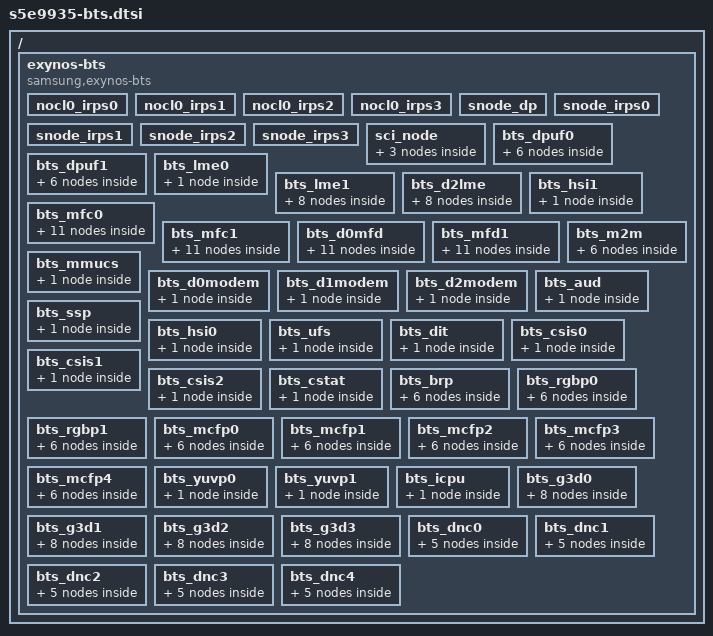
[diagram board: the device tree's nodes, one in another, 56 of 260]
/*
 * SAMSUNG EXYNOS SoC BTS device tree source
 *
 * Copyright (c) 2018 Samsung Electronics Co., Ltd.
 *		http://www.samsung.com
 *
 * SAMSUNG EXYNOS SoC BTS device nodes are listed in this file.
 * EXYNOS based board files should include this file.
 *
 * This program is free software; you can redistribute it and/or modify
 * it under the terms of the GNU General Public License version 2 as
 * published by the Free Software Foundation.
 *
 */

#include <dt-bindings/soc/samsung/exynos-bts.h>

/*
 * TREX_D_DNC		0x166F0000
 * TREX_D_NOCL0		0x1A4E0000
 * TREX_D_NOCL1A	0x1A7E0000
 * TREX_D_NOCL1B	0x1A930000
 * TREX_D_NOCL1C	0x1A6E0000
 */

/ {
	exynos-bts {
		compatible = "samsung,exynos-bts";
		acpm-ipc-channel = <8>;
		vch_pd_calid = <0xB1380017>, <0xB1380002>;
		#address-cells = <2>;
		#size-cells = <1>;
		ranges;

		list-scen = "default",
			"cp_throughput",
			"mfc_uhd",
			"mfc_uhd_10bit",
			"mfc_8k_dec30",
			"gdc_8k_8b_30",
			"gdc_8k_8b_60",
			"g3d_heavy",
			"g3d_performance",
			"dp_default",
			"camera_default",
			"npu_normal",
			"mfc_uhd_enc60",
			"camera_heavy",
			"npu_performance";

	        /* num_channel, mif_bus_width, bus_width, mif_util, int_util*/
	        bw_params = <4 16 32 65 70>;

		/* IRPS0/1/2/3 SCI_CTL_SCI_CTRL*/
		nocl0_irps0 {
			#address-cells = <2>;
			#size-cells = <1>;
			ranges;
			reg = <0x0 0x1A4EA000 0x40>;
			status = "okay";
			bts-type = <TREX_BTS>;
		};
		nocl0_irps1 {
			reg = <0x0 0x1A4EA040 0x40>;
			status = "okay";
			bts-type = <TREX_BTS>;
		};
		nocl0_irps2 {
			reg = <0x0 0x1A4EA080 0x40>;
			status = "okay";
			bts-type = <TREX_BTS>;
		};
		nocl0_irps3 {
			reg = <0x0 0x1A4EA0C0 0x40>;
			status = "okay";
			bts-type = <TREX_BTS>;
		};
		/* QMAX THRESHOLD */
		snode_dp {
			reg = <0x0 0x1A4EB040 0x8>;
			status = "okay";
			bts-type = <BUSC_BTS>;
		};
		snode_irps0 {
			reg = <0x0 0x1A4EB000 0x8>;
			status = "okay";
			bts-type = <BUSC_BTS>;
		};
		snode_irps1 {
			reg = <0x0 0x1A4EB010 0x8>;
			status = "okay";
			bts-type = <BUSC_BTS>;
		};
		snode_irps2 {
			reg = <0x0 0x1A4EB020 0x8>;
			status = "okay";
			bts-type = <BUSC_BTS>;
		};
		snode_irps3 {
			reg = <0x0 0x1A4EB030 0x8>;
			status = "okay";
			bts-type = <BUSC_BTS>;
		};
		sci_node {
			reg = <0x0 0x1A000100 0x100>;
			status = "okay";
			bts-type = <SCI_BTS>;
			default {
				stat_on = <1>;
				rmo = <0x0>;
				wmo = <0x0>;
			};
			camera_default {
				stat_on = <1>;
				rmo = <0x8>;
				wmo = <0x8>;
			};
			camera_heavy {
				stat_on = <1>;
				rmo = <0x8>;
				wmo = <0x8>;
			};
		};
		/* NOCL1A D0_DPUF0 */
		bts_dpuf0 {
			reg = <0x0 0x1A7E8000 0x80>;
			status = "okay";
			bts-type = <IP_BTS>;
			default {
				stat_on = <1>;
				bypass = <0>;
				arqos = <0x8>;
				awqos = <0x8>;
				qurgent_on = <0xC>;
				qurgent_th_r = <0x14>;
				blocking_on = <0>;
			};
			camera_default {
				stat_on = <1>;
				bypass = <0>;
				arqos = <0x8>;
				awqos = <0x8>;
				rmo = <0x20>;
				wmo = <0x20>;
				qurgent_on = <0>;
				blocking_on = <0>;
			};
			npu_normal {
				stat_on = <1>;
				bypass = <0>;
				arqos = <0x8>;
				awqos = <0x8>;
				rmo = <0x20>;
				wmo = <0x20>;
				qurgent_on = <0>;
				blocking_on = <0>;
			};
			mfc_uhd_enc60 {
				stat_on = <1>;
				bypass = <0>;
				arqos = <0x8>;
				awqos = <0x8>;
				rmo = <0x20>;
				wmo = <0x20>;
				qurgent_on = <0>;
				blocking_on = <0>;
			};
			camera_heavy {
				stat_on = <1>;
				bypass = <0>;
				arqos = <0x8>;
				awqos = <0x8>;
				rmo = <0x20>;
				wmo = <0x20>;
				qurgent_on = <0>;
				blocking_on = <0>;
			};
			npu_performance {
				stat_on = <1>;
				bypass = <0>;
				arqos = <0x8>;
				awqos = <0x8>;
				rmo = <0x20>;
				wmo = <0x20>;
				qurgent_on = <0>;
				blocking_on = <0>;
			};
		};
		/* NOCL1A D1_DPUF0 */
		bts_dpuf1 {
			reg = <0x0 0x1A7E8080 0x80>;
			status = "okay";
			bts-type = <IP_BTS>;
			default {
				stat_on = <1>;
				bypass = <0>;
				arqos = <0x8>;
				awqos = <0x8>;
				qurgent_on = <0xC>;
				qurgent_th_r = <0x14>;
				blocking_on = <0>;
			};
			camera_default {
				stat_on = <1>;
				bypass = <0>;
				arqos = <0x8>;
				awqos = <0x8>;
				rmo = <0x20>;
				wmo = <0x20>;
				qurgent_on = <0>;
				blocking_on = <0>;
			};
			npu_normal {
				stat_on = <1>;
				bypass = <0>;
				arqos = <0x8>;
				awqos = <0x8>;
				rmo = <0x20>;
				wmo = <0x20>;
				qurgent_on = <0>;
				blocking_on = <0>;
			};
			mfc_uhd_enc60 {
				stat_on = <1>;
				bypass = <0>;
				arqos = <0x8>;
				awqos = <0x8>;
				rmo = <0x20>;
				wmo = <0x20>;
				qurgent_on = <0>;
				blocking_on = <0>;
			};
			camera_heavy {
				stat_on = <1>;
				bypass = <0>;
				arqos = <0x8>;
				awqos = <0x8>;
				rmo = <0x20>;
				wmo = <0x20>;
				qurgent_on = <0>;
				blocking_on = <0>;
			};
			npu_performance {
				stat_on = <1>;
				bypass = <0>;
				arqos = <0x8>;
				awqos = <0x8>;
				rmo = <0x20>;
				wmo = <0x20>;
				qurgent_on = <0>;
				blocking_on = <0>;
			};
		};
		/* NOCL1A D0LME */
		bts_lme0 {
			reg = <0x0 0x1A7E8100 0x80>;
			status = "okay";
			bts-type = <IP_BTS>;
			default {
				stat_on = <1>;
				bypass = <0>;
				arqos = <0x4>;
				awqos = <0x4>;
				rmo = <0x4>;
				wmo = <0x8>;
				qurgent_on = <0>;
				blocking_on = <0>;
			};
		};
		/* NOCL1A D1LME */
		bts_lme1 {
			reg = <0x0 0x1A7E8180 0x80>;
			status = "okay";
			bts-type = <IP_BTS>;
			default {
				stat_on = <1>;
				bypass = <0>;
				arqos = <0x4>;
				awqos = <0x4>;
				rmo = <0x4>;
				wmo = <0x8>;
				qurgent_on = <0>;
				blocking_on = <0>;
			};
			gdc_8k_8b_30 {
				stat_on = <1>;
				bypass = <0>;
				arqos = <0x4>;
				awqos = <0x4>;
				rmo = <0x3C>;
				wmo = <0x14>;
				qurgent_on = <0>;
				blocking_on = <0>;
			};
			gdc_8k_8b_60 {
				stat_on = <1>;
				bypass = <0>;
				arqos = <0x4>;
				awqos = <0x4>;
				rmo = <0x84>;
				wmo = <0x28>;
				qurgent_on = <0>;
				blocking_on = <0>;
			};
			camera_default {
				stat_on = <1>;
				bypass = <0>;
				arqos = <0x4>;
				awqos = <0x4>;
				rmo = <0x28>;
				wmo = <0x8>;
				qurgent_on = <0>;
				blocking_on = <0>;
			};
			npu_normal {
				stat_on = <1>;
				bypass = <0>;
				arqos = <0x4>;
				awqos = <0x4>;
				rmo = <0x28>;
				wmo = <0x8>;
				qurgent_on = <0>;
				blocking_on = <0>;
			};
			mfc_uhd_enc60 {
				stat_on = <1>;
				bypass = <0>;
				arqos = <0x4>;
				awqos = <0x4>;
				rmo = <0x4>;
				wmo = <0x8>;
				qurgent_on = <0>;
				blocking_on = <0>;
			};
			camera_heavy {
				stat_on = <1>;
				bypass = <0>;
				arqos = <0x4>;
				awqos = <0x4>;
				rmo = <0x28>;
				wmo = <0x8>;
				qurgent_on = <0>;
				blocking_on = <0>;
			};
			npu_performance {
				stat_on = <1>;
				bypass = <0>;
				arqos = <0x4>;
				awqos = <0x4>;
				rmo = <0x4>;
				wmo = <0x8>;
				qurgent_on = <0>;
				blocking_on = <0>;
			};
		};
		/* NOCL1A D2LME */
		bts_d2lme {
			reg = <0x0 0x1A7E8200 0x80>;
			status = "okay";
			bts-type = <IP_BTS>;
			default {
				stat_on = <1>;
				bypass = <0>;
				arqos = <0x4>;
				awqos = <0x4>;
				rmo = <0xC>;
				wmo = <0xC>;
				qurgent_on = <0>;
				blocking_on = <0>;
			};
			gdc_8k_8b_30 {
				stat_on = <1>;
				bypass = <0>;
				arqos = <0x4>;
				awqos = <0x4>;
				rmo = <0xC>;
				wmo = <0xC>;
				qurgent_on = <0>;
				blocking_on = <0>;
			};
			gdc_8k_8b_60 {
				stat_on = <1>;
				bypass = <0>;
				arqos = <0x4>;
				awqos = <0x4>;
				rmo = <0xC>;
				wmo = <0xC>;
				qurgent_on = <0>;
				blocking_on = <0>;
			};
			camera_default {
				stat_on = <1>;
				bypass = <0>;
				arqos = <0x4>;
				awqos = <0x4>;
				rmo = <0xC>;
				wmo = <0xC>;
				qurgent_on = <0>;
				blocking_on = <0>;
			};
			npu_normal {
				stat_on = <1>;
				bypass = <0>;
				arqos = <0x4>;
				awqos = <0x4>;
				rmo = <0xC>;
				wmo = <0xC>;
				qurgent_on = <0>;
				blocking_on = <0>;
			};
			mfc_uhd_enc60 {
				stat_on = <1>;
				bypass = <0>;
				arqos = <0x4>;
				awqos = <0x4>;
				rmo = <0xC>;
				wmo = <0xC>;
				qurgent_on = <0>;
				blocking_on = <0>;
			};
			camera_heavy {
				stat_on = <1>;
				bypass = <0>;
				arqos = <0x4>;
				awqos = <0x4>;
				rmo = <0xE>;
				wmo = <0xE>;
				qurgent_on = <0>;
				blocking_on = <0>;
			};
			npu_performance {
				stat_on = <1>;
				bypass = <0>;
				arqos = <0x4>;
				awqos = <0x4>;
				rmo = <0xC>;
				wmo = <0xC>;
				qurgent_on = <0>;
				blocking_on = <0>;
			};
		};
		/* NOCL1A HSI1 */
		bts_hsi1 {
			reg = <0x0 0x1A7E8280 0x80>;
			status = "okay";
			bts-type = <IP_BTS>;
			default {
				stat_on = <1>;
				bypass = <0>;
				arqos = <0x4>;
				awqos = <0x4>;
				rmo = <0x4>;
				wmo = <0x4>;
				qurgent_on = <0>;
				blocking_on = <1>;
				qmax0_limit_r = <0x1>;
				qmax0_limit_w = <0x1>;
			};
		};
		/* NOCL1A D0_MFC */
		bts_mfc0 {
			reg = <0x0 0x1A7E8300 0x80>;
			status = "okay";
			bts-type = <IP_BTS>;
			default {
				stat_on = <1>;
				bypass = <0>;
				arqos = <0x4>;
				awqos = <0x4>;
				rmo = <0x1C>;
				wmo = <0xC>;
				qurgent_on = <0>;
				blocking_on = <0>;
			};
			mfc_uhd {
				stat_on = <1>;
				bypass = <0>;
				arqos = <0x4>;
				awqos = <0x4>;
				rmo = <0x20>;
				wmo = <0x20>;
				qurgent_on = <0>;
				blocking_on = <0>;
			};
			mfc_uhd_10bit {
				stat_on = <1>;
				bypass = <0>;
				arqos = <0x4>;
				awqos = <0x4>;
				rmo = <0x20>;
				wmo = <0x20>;
				qurgent_on = <0>;
				blocking_on = <0>;
			};
			mfc_8k_dec30 {
				stat_on = <1>;
				bypass = <0>;
				arqos = <0x4>;
				awqos = <0x4>;
				rmo = <0x40>;
				wmo = <0x40>;
				qurgent_on = <0>;
				blocking_on = <0>;
			};
			g3d_performance {
				stat_on = <1>;
				bypass = <0>;
				arqos = <0x4>;
				awqos = <0x4>;
				rmo = <0x20>;
				wmo = <0x20>;
				qurgent_on = <0>;
				blocking_on = <0>;
			};
			dp_default {
				stat_on = <1>;
				bypass = <0>;
				arqos = <0x4>;
				awqos = <0x4>;
				rmo = <0x20>;
				wmo = <0x20>;
				qurgent_on = <0>;
				blocking_on = <0>;
			};
			camera_default {
				stat_on = <1>;
				bypass = <0>;
				arqos = <0x4>;
				awqos = <0x4>;
				rmo = <0x1C>;
				wmo = <0xC>;
				qurgent_on = <0>;
				blocking_on = <0>;
			};
			npu_normal {
				stat_on = <1>;
				bypass = <0>;
				arqos = <0x4>;
				awqos = <0x4>;
				rmo = <0x1C>;
				wmo = <0xC>;
				qurgent_on = <0>;
				blocking_on = <0>;
			};
			mfc_uhd_enc60 {
				stat_on = <1>;
				bypass = <0>;
				arqos = <0x4>;
				awqos = <0x4>;
				rmo = <0x20>;
				wmo = <0x20>;
				qurgent_on = <0>;
				blocking_on = <0>;
			};
			camera_heavy {
				stat_on = <1>;
				bypass = <0>;
				arqos = <0x4>;
				awqos = <0x4>;
				rmo = <0x1C>;
				wmo = <0xC>;
				qurgent_on = <0>;
				blocking_on = <0>;
			};
			npu_performance {
				stat_on = <1>;
				bypass = <0>;
				arqos = <0x4>;
				awqos = <0x4>;
				rmo = <0x1C>;
				wmo = <0xC>;
				qurgent_on = <0>;
				blocking_on = <0>;
			};
		};
		/* NOCL1A D1_MFC */
		bts_mfc1 {
			reg = <0x0 0x1A7E8380 0x80>;
			status = "okay";
			bts-type = <IP_BTS>;
			default {
				stat_on = <1>;
				bypass = <0>;
				arqos = <0x4>;
				awqos = <0x4>;
				rmo = <0x1C>;
				wmo = <0xC>;
				qurgent_on = <0>;
				blocking_on = <0>;
			};
			mfc_uhd {
				stat_on = <1>;
				bypass = <0>;
				arqos = <0x4>;
				awqos = <0x4>;
				rmo = <0x20>;
				wmo = <0x20>;
				qurgent_on = <0>;
				blocking_on = <0>;
			};
			mfc_uhd_10bit {
				stat_on = <1>;
				bypass = <0>;
				arqos = <0x4>;
				awqos = <0x4>;
				rmo = <0x20>;
				wmo = <0x20>;
				qurgent_on = <0>;
				blocking_on = <0>;
			};
			mfc_8k_dec30 {
				stat_on = <1>;
				bypass = <0>;
				arqos = <0x4>;
				awqos = <0x4>;
				rmo = <0x40>;
				wmo = <0x40>;
				qurgent_on = <0>;
				blocking_on = <0>;
			};
			g3d_performance {
				stat_on = <1>;
				bypass = <0>;
				arqos = <0x4>;
				awqos = <0x4>;
				rmo = <0x20>;
				wmo = <0x20>;
				qurgent_on = <0>;
				blocking_on = <0>;
			};
			dp_default {
				stat_on = <1>;
				bypass = <0>;
				arqos = <0x4>;
				awqos = <0x4>;
				rmo = <0x20>;
				wmo = <0x20>;
				qurgent_on = <0>;
				blocking_on = <0>;
			};
			camera_default {
				stat_on = <1>;
				bypass = <0>;
				arqos = <0x4>;
				awqos = <0x4>;
				rmo = <0x1C>;
				wmo = <0xC>;
				qurgent_on = <0>;
				blocking_on = <0>;
			};
			npu_normal {
				stat_on = <1>;
				bypass = <0>;
				arqos = <0x4>;
				awqos = <0x4>;
				rmo = <0x1C>;
				wmo = <0xC>;
				qurgent_on = <0>;
				blocking_on = <0>;
			};
			mfc_uhd_enc60 {
				stat_on = <1>;
				bypass = <0>;
				arqos = <0x4>;
				awqos = <0x4>;
				rmo = <0x20>;
				wmo = <0x20>;
				qurgent_on = <0>;
				blocking_on = <0>;
			};
			camera_heavy {
				stat_on = <1>;
				bypass = <0>;
				arqos = <0x4>;
				awqos = <0x4>;
				rmo = <0x1C>;
				wmo = <0xC>;
				qurgent_on = <0>;
				blocking_on = <0>;
			};
			npu_performance {
				stat_on = <1>;
				bypass = <0>;
				arqos = <0x4>;
				awqos = <0x4>;
				rmo = <0x1C>;
				wmo = <0xC>;
				qurgent_on = <0>;
				blocking_on = <0>;
			};
		};
		/* NOCL1A D0_MFD */
		bts_d0mfd {
			reg = <0x0 0x1A7E8400 0x80>;
			status = "okay";
			bts-type = <IP_BTS>;
			default {
				stat_on = <1>;
				bypass = <0>;
				arqos = <0x4>;
				awqos = <0x4>;
				rmo = <0x1C>;
				wmo = <0xC>;
				qurgent_on = <0>;
				blocking_on = <0>;
			};
			mfc_uhd {
				stat_on = <1>;
				bypass = <0>;
				arqos = <0x4>;
				awqos = <0x4>;
				rmo = <0x20>;
				wmo = <0x20>;
				qurgent_on = <0>;
				blocking_on = <0>;
			};
			mfc_uhd_10bit {
				stat_on = <1>;
				bypass = <0>;
				arqos = <0x4>;
				awqos = <0x4>;
				rmo = <0x20>;
				wmo = <0x20>;
				qurgent_on = <0>;
				blocking_on = <0>;
			};
			mfc_8k_dec30 {
				stat_on = <1>;
				bypass = <0>;
				arqos = <0x4>;
				awqos = <0x4>;
				rmo = <0x40>;
				wmo = <0x40>;
				qurgent_on = <0>;
				blocking_on = <0>;
			};
			g3d_performance {
				stat_on = <1>;
				bypass = <0>;
				arqos = <0x4>;
				awqos = <0x4>;
				rmo = <0x20>;
				wmo = <0x20>;
				qurgent_on = <0>;
				blocking_on = <0>;
			};
			dp_default {
				stat_on = <1>;
				bypass = <0>;
				arqos = <0x4>;
				awqos = <0x4>;
				rmo = <0x20>;
				wmo = <0x20>;
				qurgent_on = <0>;
				blocking_on = <0>;
			};
			camera_default {
				stat_on = <1>;
				bypass = <0>;
				arqos = <0x4>;
				awqos = <0x4>;
				rmo = <0x1C>;
				wmo = <0xC>;
				qurgent_on = <0>;
				blocking_on = <0>;
			};
			npu_normal {
				stat_on = <1>;
				bypass = <0>;
				arqos = <0x4>;
				awqos = <0x4>;
				rmo = <0x1C>;
				wmo = <0xC>;
				qurgent_on = <0>;
				blocking_on = <0>;
			};
			mfc_uhd_enc60 {
				stat_on = <1>;
				bypass = <0>;
				arqos = <0x4>;
				awqos = <0x4>;
				rmo = <0x20>;
				wmo = <0x20>;
				qurgent_on = <0>;
				blocking_on = <0>;
			};
			camera_heavy {
				stat_on = <1>;
				bypass = <0>;
				arqos = <0x4>;
				awqos = <0x4>;
				rmo = <0x1C>;
				wmo = <0xC>;
				qurgent_on = <0>;
				blocking_on = <0>;
			};
			npu_performance {
				stat_on = <1>;
				bypass = <0>;
				arqos = <0x4>;
				awqos = <0x4>;
				rmo = <0x20>;
				wmo = <0x20>;
				qurgent_on = <0>;
				blocking_on = <0>;
			};
		};
		/* NOCL1A D1_MFD */
		bts_mfd1 {
			reg = <0x0 0x1A7E8480 0x80>;
			status = "okay";
			bts-type = <IP_BTS>;
			default {
				stat_on = <1>;
				bypass = <0>;
				arqos = <0x4>;
				awqos = <0x4>;
				rmo = <0x1C>;
				wmo = <0xC>;
				qurgent_on = <0>;
				blocking_on = <0>;
			};
			mfc_uhd {
				stat_on = <1>;
				bypass = <0>;
				arqos = <0x4>;
				awqos = <0x4>;
				rmo = <0x20>;
				wmo = <0x20>;
				qurgent_on = <0>;
				blocking_on = <0>;
			};
			mfc_uhd_10bit {
				stat_on = <1>;
				bypass = <0>;
				arqos = <0x4>;
				awqos = <0x4>;
				rmo = <0x20>;
				wmo = <0x20>;
				qurgent_on = <0>;
				blocking_on = <0>;
			};
			mfc_8k_dec30 {
				stat_on = <1>;
				bypass = <0>;
				arqos = <0x4>;
				awqos = <0x4>;
				rmo = <0x40>;
				wmo = <0x40>;
				qurgent_on = <0>;
				blocking_on = <0>;
			};
			g3d_performance {
				stat_on = <1>;
				bypass = <0>;
				arqos = <0x4>;
				awqos = <0x4>;
				rmo = <0x20>;
				wmo = <0x20>;
				qurgent_on = <0>;
				blocking_on = <0>;
			};
			dp_default {
				stat_on = <1>;
				bypass = <0>;
				arqos = <0x4>;
				awqos = <0x4>;
				rmo = <0x20>;
				wmo = <0x20>;
				qurgent_on = <0>;
				blocking_on = <0>;
			};
			camera_default {
				stat_on = <1>;
				bypass = <0>;
				arqos = <0x4>;
				awqos = <0x4>;
				rmo = <0x1C>;
				wmo = <0xC>;
				qurgent_on = <0>;
				blocking_on = <0>;
			};
			npu_normal {
				stat_on = <1>;
				bypass = <0>;
				arqos = <0x4>;
				awqos = <0x4>;
				rmo = <0x1C>;
				wmo = <0xC>;
				qurgent_on = <0>;
				blocking_on = <0>;
			};
			mfc_uhd_enc60 {
				stat_on = <1>;
				bypass = <0>;
				arqos = <0x4>;
				awqos = <0x4>;
				rmo = <0x20>;
				wmo = <0x20>;
				qurgent_on = <0>;
				blocking_on = <0>;
			};
			camera_heavy {
				stat_on = <1>;
				bypass = <0>;
				arqos = <0x4>;
				awqos = <0x4>;
				rmo = <0x1C>;
				wmo = <0xC>;
				qurgent_on = <0>;
				blocking_on = <0>;
			};
			npu_performance {
				stat_on = <1>;
				bypass = <0>;
				arqos = <0x4>;
				awqos = <0x4>;
				rmo = <0x1C>;
				wmo = <0xC>;
				qurgent_on = <0>;
				blocking_on = <0>;
			};
		};
		/* NOCL1A M2M */
		bts_m2m {
			reg = <0x0 0x1A7E8500 0x100>;
			status = "okay";
			bts-type = <IP_BTS>;
			default {
				stat_on = <1>;
				bypass = <0>;
				arqos = <0x4>;
				awqos = <0x4>;
				rmo = <0x18>;
				wmo = <0x18>;
				qurgent_on = <0>;
				blocking_on = <1>;
				qmax0_limit_r = <0x8>;
				qmax0_limit_w = <0x8>;
			};
			camera_default {
				stat_on = <1>;
				bypass = <0>;
				arqos = <0x4>;
				awqos = <0x4>;
				rmo = <0x8>;
				wmo = <0x8>;
				qurgent_on = <0>;
				blocking_on = <0>;
			};
			npu_normal {
				stat_on = <1>;
				bypass = <0>;
				arqos = <0x4>;
				awqos = <0x4>;
				rmo = <0x8>;
				wmo = <0x8>;
				qurgent_on = <0>;
				blocking_on = <0>;
			};
			mfc_uhd_enc60 {
				stat_on = <1>;
				bypass = <0>;
				arqos = <0x4>;
				awqos = <0x4>;
				rmo = <0x8>;
				wmo = <0x8>;
				qurgent_on = <0>;
				blocking_on = <0>;
			};
			camera_heavy {
				stat_on = <1>;
				bypass = <0>;
				arqos = <0x4>;
				awqos = <0x4>;
				rmo = <0x20>;
				wmo = <0x20>;
				qurgent_on = <0>;
				blocking_on = <0>;
			};
			npu_performance {
				stat_on = <1>;
				bypass = <0>;
				arqos = <0x4>;
				awqos = <0x4>;
				rmo = <0x8>;
				wmo = <0x8>;
				qurgent_on = <0>;
				blocking_on = <0>;
			};
		};
		/* NOCL0 MMUCS */
		bts_mmucs {
			reg = <0x0 0x1A4E8000 0x80>;
			status = "okay";
			bts-type = <IP_BTS>;
			default {
				stat_on = <1>;
				bypass = <0>;
				arqos = <0x4>;
				awqos = <0x4>;
				rmo = <0x4>;
				wmo = <0x4>;
				qurgent_on = <0x0>;
				blocking_on = <0>;
			};
		};
		/* NOCL0 D0_MODEM */
		bts_d0modem {
			reg = <0x0 0x1A4E8080 0x80>;
			status = "okay";
			bts-type = <IP_BTS>;
			default {
				stat_on = <1>;
				bypass = <0>;
				arqos = <0xC>;
				awqos = <0xC>;
				rmo = <0x20>;
				wmo = <0x20>;
				qurgent_on = <0xC>;
				qurgent_th_r = <0x14>;
				qurgent_th_w = <0x14>;
				blocking_on = <0>;
			};
		};
		/* NOCL0 D1_MODEM */
		bts_d1modem {
			reg = <0x0 0x1A4E8100 0x80>;
			status = "okay";
			bts-type = <IP_BTS>;
			default {
				stat_on = <1>;
				bypass = <1>;
				rmo = <0x14>;
				wmo = <0x14>;
				qurgent_on = <0>;
				blocking_on = <0>;
			};
		};
		/* NOCL0 D2_MODEM */
		bts_d2modem {
			reg = <0x0 0x1A4E8180 0x80>;
			status = "okay";
			bts-type = <IP_BTS>;
			default {
				stat_on = <1>;
				bypass = <0>;
				arqos = <0x4>;
				awqos = <0x4>;
				rmo = <0x14>;
				wmo = <0x8>;
				qurgent_on = <0x0>;
				blocking_on = <0>;
			};
		};
		/* NOCL0 AUD */
		bts_aud {
			reg = <0x0 0x1A4E8200 0x80>;
			status = "okay";
			bts-type = <IP_BTS>;
			default {
				stat_on = <1>;
				bypass = <0>;
				arqos = <0x9>;
				awqos = <0x9>;
				qurgent_on = <0xC>;
				qurgent_th_r = <0x14>;
				qurgent_th_w = <0x14>;
				blocking_on = <0>;
			};
		};
		/* NOCL0 SSP */
		bts_ssp {
			reg = <0x0 0x1A4E8280 0x80>;
			status = "okay";
			bts-type = <IP_BTS>;
			default {
				stat_on = <1>;
				bypass = <0>;
				arqos = <0x4>;
				awqos = <0x4>;
				rmo = <0x4>;
				wmo = <0x4>;
				qurgent_on = <0>;
				blocking_on = <0>;
			};
		};
		/* NOCL1B HSI0 */
		bts_hsi0 {
			reg = <0x0 0x1A938000 0x80>;
			status = "okay";
			bts-type = <IP_BTS>;
			default {
				stat_on = <1>;
				bypass = <0>;
				arqos = <0x4>;
				awqos = <0x4>;
				rmo = <0x4>;
				wmo = <0x4>;
				qurgent_on = <0>;
				blocking_on = <1>;
				qmax0_limit_r = <0x1>;
				qmax0_limit_w = <0x1>;
			};
		};
		/* NOCL1B ufs */
		bts_ufs {
			reg = <0x0 0x1A938080 0x80>;
			status = "okay";
			bts-type = <IP_BTS>;
			default {
				stat_on = <1>;
				bypass = <0>;
				arqos = <0x4>;
				awqos = <0x4>;
				rmo = <0xC>;
				wmo = <0xC>;
				qurgent_on = <0>;
				blocking_on = <1>;
				qmax0_limit_r = <0x1>;
				qmax0_limit_w = <0x1>;
			};
		};
		/* NOCL1B DIT */
		bts_dit {
			reg = <0x0 0x1A938100 0x80>;
			status = "okay";
			bts-type = <IP_BTS>;
			default {
				stat_on = <1>;
				bypass = <0>;
				arqos = <0x4>;
				awqos = <0x4>;
				rmo = <0x4>;
				wmo = <0x4>;
				qurgent_on = <0>;
				blocking_on = <1>;
				qmax0_limit_r = <0x1>;
				qmax0_limit_w = <0x1>;
			};
		};
		/* NOCL1C D0_CSIS */
		bts_csis0 {
			reg = <0x0 0x1A6E8000 0x80>;
			status = "okay";
			bts-type = <IP_BTS>;
			cal-pdid = <0xB1380002>;
			default {
				stat_on = <1>;
				bypass = <0>;
				arqos = <0xC>;
				awqos = <0xC>;
				qurgent_on = <0xC>;
				qurgent_th_r = <0x14>;
				qurgent_th_w = <0xD>;
				blocking_on = <0>;
			};
		};
		/* NOCL1C D1_CSIS */
		bts_csis1 {
			reg = <0x0 0x1A6E8080 0x80>;
			status = "okay";
			bts-type = <IP_BTS>;
			cal-pdid = <0xB1380002>;
			default {
				stat_on = <1>;
				bypass = <0>;
				arqos = <0xC>;
				awqos = <0xC>;
				qurgent_on = <0xC>;
				qurgent_th_r = <0x14>;
				qurgent_th_w = <0xD>;
				blocking_on = <0>;
			};
		};
		/* NOCL1C D2_CSIS */
		bts_csis2 {
			reg = <0x0 0x1A6E8100 0x80>;
			status = "okay";
			bts-type = <IP_BTS>;
			cal-pdid = <0xB1380002>;
			default {
				stat_on = <1>;
				bypass = <0>;
				arqos = <0xC>;
				awqos = <0xC>;
				qurgent_on = <0xC>;
				qurgent_th_r = <0x14>;
				qurgent_th_w = <0xD>;
				blocking_on = <0>;
			};
		};
		/* NOCL1C CSTAT */
		bts_cstat {
			reg = <0x0 0x1A6E8180 0x80>;
			status = "okay";
			bts-type = <IP_BTS>;
			cal-pdid = <0xB1380002>;
			default {
				stat_on = <1>;
				bypass = <0>;
				arqos = <0xC>;
				awqos = <0xC>;
				qurgent_on = <0xC>;
				qurgent_th_r = <0x14>;
				qurgent_th_w = <0xD>;
				blocking_on = <0>;
			};
		};
		/* NOCL1C BRP */
		bts_brp {
			reg = <0x0 0x1A6E8200 0x80>;
			status = "okay";
			bts-type = <IP_BTS>;
			cal-pdid = <0xB1380002>;
			default {
				stat_on = <1>;
				bypass = <0>;
				arqos = <0x4>;
				awqos = <0x4>;
				rmo = <0x4>;
				wmo = <0x8>;
				qurgent_on = <0>;
				blocking_on = <0>;
			};
			camera_default {
				stat_on = <1>;
				bypass = <0>;
				arqos = <0x4>;
				awqos = <0x4>;
				rmo = <0x10>;
				wmo = <0x8>;
				qurgent_on = <0>;
				blocking_on = <0>;
			};
			npu_normal {
				stat_on = <1>;
				bypass = <0>;
				arqos = <0x4>;
				awqos = <0x4>;
				rmo = <0x10>;
				wmo = <0x8>;
				qurgent_on = <0>;
				blocking_on = <0>;
			};
			mfc_uhd_enc60 {
				stat_on = <1>;
				bypass = <0>;
				arqos = <0x4>;
				awqos = <0x4>;
				rmo = <0x4>;
				wmo = <0x8>;
				qurgent_on = <0>;
				blocking_on = <0>;
			};
			camera_heavy {
				stat_on = <1>;
				bypass = <0>;
				arqos = <0x4>;
				awqos = <0x4>;
				rmo = <0x20>;
				wmo = <0x20>;
				qurgent_on = <0>;
				blocking_on = <0>;
			};
			npu_performance {
				stat_on = <1>;
				bypass = <0>;
				arqos = <0x4>;
				awqos = <0x4>;
				rmo = <0x4>;
				wmo = <0x8>;
				qurgent_on = <0>;
				blocking_on = <0>;
			};

		};
		/* NOCL1C D0_RGBP */
		bts_rgbp0 {
			reg = <0x0 0x1A6E8280 0x80>;
			status = "okay";
			bts-type = <IP_BTS>;
			cal-pdid = <0xB1380002>;
			default {
				stat_on = <1>;
				bypass = <0>;
				arqos = <0x4>;
				awqos = <0x4>;
				rmo = <0x4>;
				wmo = <0x8>;
				qurgent_on = <0>;
				blocking_on = <0>;
			};
			camera_default {
				stat_on = <1>;
				bypass = <0>;
				arqos = <0x4>;
				awqos = <0x4>;
				rmo = <0x10>;
				wmo = <0x8>;
				qurgent_on = <0>;
				blocking_on = <0>;
			};
			npu_normal {
				stat_on = <1>;
				bypass = <0>;
				arqos = <0x4>;
				awqos = <0x4>;
				rmo = <0x10>;
				wmo = <0x8>;
				qurgent_on = <0>;
				blocking_on = <0>;
			};
			mfc_uhd_enc60 {
				stat_on = <1>;
				bypass = <0>;
				arqos = <0x4>;
				awqos = <0x4>;
				rmo = <0x4>;
				wmo = <0x8>;
				qurgent_on = <0>;
				blocking_on = <0>;
			};
			camera_heavy {
				stat_on = <1>;
				bypass = <0>;
				arqos = <0x4>;
				awqos = <0x4>;
				rmo = <0x20>;
				wmo = <0x20>;
				qurgent_on = <0>;
				blocking_on = <0>;
			};
			npu_performance {
				stat_on = <1>;
				bypass = <0>;
				arqos = <0x4>;
				awqos = <0x4>;
				rmo = <0x4>;
				wmo = <0x8>;
				qurgent_on = <0>;
				blocking_on = <0>;
			};

		};
		/* NOCL1C D1_RGBP */
		bts_rgbp1 {
			reg = <0x0 0x1A6E8300 0x80>;
			status = "okay";
			bts-type = <IP_BTS>;
			cal-pdid = <0xB1380002>;
			default {
				stat_on = <1>;
				bypass = <0>;
				arqos = <0x4>;
				awqos = <0x4>;
				rmo = <0x4>;
				wmo = <0x8>;
				qurgent_on = <0>;
				blocking_on = <0>;
			};
			camera_default {
				stat_on = <1>;
				bypass = <0>;
				arqos = <0x4>;
				awqos = <0x4>;
				rmo = <0x10>;
				wmo = <0x8>;
				qurgent_on = <0>;
				blocking_on = <0>;
			};
			npu_normal {
				stat_on = <1>;
				bypass = <0>;
				arqos = <0x4>;
				awqos = <0x4>;
				rmo = <0x10>;
				wmo = <0x8>;
				qurgent_on = <0>;
				blocking_on = <0>;
			};
			mfc_uhd_enc60 {
				stat_on = <1>;
				bypass = <0>;
				arqos = <0x4>;
				awqos = <0x4>;
				rmo = <0x4>;
				wmo = <0x8>;
				qurgent_on = <0>;
				blocking_on = <0>;
			};
			camera_heavy {
				stat_on = <1>;
				bypass = <0>;
				arqos = <0x4>;
				awqos = <0x4>;
				rmo = <0x20>;
				wmo = <0x20>;
				qurgent_on = <0>;
				blocking_on = <0>;
			};
			npu_performance {
				stat_on = <1>;
				bypass = <0>;
				arqos = <0x4>;
				awqos = <0x4>;
				rmo = <0x4>;
				wmo = <0x8>;
				qurgent_on = <0>;
				blocking_on = <0>;
			};

		};
		/* NOCL1C D0_MCFP */
		bts_mcfp0 {
			reg = <0x0 0x1A6E8380 0x80>;
			status = "okay";
			bts-type = <IP_BTS>;
			cal-pdid = <0xB1380002>;
			default {
				stat_on = <1>;
				bypass = <0>;
				arqos = <0x4>;
				awqos = <0x4>;
				rmo = <0x8>;
				wmo = <0x8>;
				qurgent_on = <0>;
				blocking_on = <0>;
			};
			camera_default {
				stat_on = <1>;
				bypass = <0>;
				arqos = <0x4>;
				awqos = <0x4>;
				rmo = <0x10>;
				wmo = <0x8>;
				qurgent_on = <0>;
				blocking_on = <0>;
			};
			npu_normal {
				stat_on = <1>;
				bypass = <0>;
				arqos = <0x4>;
				awqos = <0x4>;
				rmo = <0x10>;
				wmo = <0x8>;
				qurgent_on = <0>;
				blocking_on = <0>;
			};
			mfc_uhd_enc60 {
				stat_on = <1>;
				bypass = <0>;
				arqos = <0x4>;
				awqos = <0x4>;
				rmo = <0x8>;
				wmo = <0x8>;
				qurgent_on = <0>;
				blocking_on = <0>;
			};
			camera_heavy {
				stat_on = <1>;
				bypass = <0>;
				arqos = <0x4>;
				awqos = <0x4>;
				rmo = <0x20>;
				wmo = <0x20>;
				qurgent_on = <0>;
				blocking_on = <0>;
			};
			npu_performance {
				stat_on = <1>;
				bypass = <0>;
				arqos = <0x4>;
				awqos = <0x4>;
				rmo = <0x8>;
				wmo = <0x8>;
				qurgent_on = <0>;
				blocking_on = <0>;
			};
		};
		/* NOCL1C D1_MCFP */
		bts_mcfp1 {
			reg = <0x0 0x1A6E8400 0x80>;
			status = "okay";
			bts-type = <IP_BTS>;
			cal-pdid = <0xB1380002>;
			default {
				stat_on = <1>;
				bypass = <0>;
				arqos = <0x4>;
				awqos = <0x4>;
				rmo = <0x8>;
				wmo = <0x8>;
				qurgent_on = <0>;
				blocking_on = <0>;
			};
			camera_default {
				stat_on = <1>;
				bypass = <0>;
				arqos = <0x4>;
				awqos = <0x4>;
				rmo = <0x10>;
				wmo = <0x10>;
				qurgent_on = <0>;
				blocking_on = <0>;
			};
			npu_normal {
				stat_on = <1>;
				bypass = <0>;
				arqos = <0x4>;
				awqos = <0x4>;
				rmo = <0x10>;
				wmo = <0x10>;
				qurgent_on = <0>;
				blocking_on = <0>;
			};
			mfc_uhd_enc60 {
				stat_on = <1>;
				bypass = <0>;
				arqos = <0x4>;
				awqos = <0x4>;
				rmo = <0x8>;
				wmo = <0x8>;
				qurgent_on = <0>;
				blocking_on = <0>;
			};
			camera_heavy {
				stat_on = <1>;
				bypass = <0>;
				arqos = <0x4>;
				awqos = <0x4>;
				rmo = <0x20>;
				wmo = <0x20>;
				qurgent_on = <0>;
				blocking_on = <0>;
			};
			npu_performance {
				stat_on = <1>;
				bypass = <0>;
				arqos = <0x4>;
				awqos = <0x4>;
				rmo = <0x8>;
				wmo = <0x8>;
				qurgent_on = <0>;
				blocking_on = <0>;
			};
		};
		/* NOCL1C D2_MCFP */
		bts_mcfp2 {
			reg = <0x0 0x1A6E8480 0x80>;
			status = "okay";
			bts-type = <IP_BTS>;
			cal-pdid = <0xB1380002>;
			default {
				stat_on = <1>;
				bypass = <0>;
				arqos = <0x4>;
				awqos = <0x4>;
				rmo = <0x8>;
				wmo = <0x8>;
				qurgent_on = <0>;
				blocking_on = <0>;
			};
			camera_default {
				stat_on = <1>;
				bypass = <0>;
				arqos = <0x4>;
				awqos = <0x4>;
				rmo = <0x10>;
				wmo = <0x10>;
				qurgent_on = <0>;
				blocking_on = <0>;
			};
			npu_normal {
				stat_on = <1>;
				bypass = <0>;
				arqos = <0x4>;
				awqos = <0x4>;
				rmo = <0x10>;
				wmo = <0x10>;
				qurgent_on = <0>;
				blocking_on = <0>;
			};
			mfc_uhd_enc60 {
				stat_on = <1>;
				bypass = <0>;
				arqos = <0x4>;
				awqos = <0x4>;
				rmo = <0x8>;
				wmo = <0x8>;
				qurgent_on = <0>;
				blocking_on = <0>;
			};
			camera_heavy {
				stat_on = <1>;
				bypass = <0>;
				arqos = <0x4>;
				awqos = <0x4>;
				rmo = <0x20>;
				wmo = <0x20>;
				qurgent_on = <0>;
				blocking_on = <0>;
			};
			npu_performance {
				stat_on = <1>;
				bypass = <0>;
				arqos = <0x4>;
				awqos = <0x4>;
				rmo = <0x8>;
				wmo = <0x8>;
				qurgent_on = <0>;
				blocking_on = <0>;
			};
		};
		/* NOCL1C D3_MCFP */
		bts_mcfp3 {
			reg = <0x0 0x1A6E8500 0x80>;
			status = "okay";
			bts-type = <IP_BTS>;
			cal-pdid = <0xB1380002>;
			default {
				stat_on = <1>;
				bypass = <0>;
				arqos = <0x4>;
				awqos = <0x4>;
				rmo = <0x8>;
				wmo = <0x8>;
				qurgent_on = <0>;
				blocking_on = <0>;
			};
			camera_default {
				stat_on = <1>;
				bypass = <0>;
				arqos = <0x4>;
				awqos = <0x4>;
				rmo = <0x10>;
				wmo = <0x10>;
				qurgent_on = <0>;
				blocking_on = <0>;
			};
			npu_normal {
				stat_on = <1>;
				bypass = <0>;
				arqos = <0x4>;
				awqos = <0x4>;
				rmo = <0x10>;
				wmo = <0x10>;
				qurgent_on = <0>;
				blocking_on = <0>;
			};
			mfc_uhd_enc60 {
				stat_on = <1>;
				bypass = <0>;
				arqos = <0x4>;
				awqos = <0x4>;
				rmo = <0x8>;
				wmo = <0x8>;
				qurgent_on = <0>;
				blocking_on = <0>;
			};
			camera_heavy {
				stat_on = <1>;
				bypass = <0>;
				arqos = <0x4>;
				awqos = <0x4>;
				rmo = <0x20>;
				wmo = <0x20>;
				qurgent_on = <0>;
				blocking_on = <0>;
			};
			npu_performance {
				stat_on = <1>;
				bypass = <0>;
				arqos = <0x4>;
				awqos = <0x4>;
				rmo = <0x8>;
				wmo = <0x8>;
				qurgent_on = <0>;
				blocking_on = <0>;
			};
		};
		/* NOCL1C D4_MCFP */
		bts_mcfp4 {
			reg = <0x0 0x1A6E8580 0x80>;
			status = "okay";
			bts-type = <IP_BTS>;
			cal-pdid = <0xB1380002>;
			default {
				stat_on = <1>;
				bypass = <0>;
				arqos = <0x4>;
				awqos = <0x4>;
				rmo = <0x8>;
				wmo = <0x8>;
				qurgent_on = <0>;
				blocking_on = <0>;
			};
			camera_default {
				stat_on = <1>;
				bypass = <0>;
				arqos = <0x4>;
				awqos = <0x4>;
				rmo = <0x10>;
				wmo = <0x10>;
				qurgent_on = <0>;
				blocking_on = <0>;
			};
			npu_normal {
				stat_on = <1>;
				bypass = <0>;
				arqos = <0x4>;
				awqos = <0x4>;
				rmo = <0x10>;
				wmo = <0x10>;
				qurgent_on = <0>;
				blocking_on = <0>;
			};
			mfc_uhd_enc60 {
				stat_on = <1>;
				bypass = <0>;
				arqos = <0x4>;
				awqos = <0x4>;
				rmo = <0x8>;
				wmo = <0x8>;
				qurgent_on = <0>;
				blocking_on = <0>;
			};
			camera_heavy {
				stat_on = <1>;
				bypass = <0>;
				arqos = <0x4>;
				awqos = <0x4>;
				rmo = <0x20>;
				wmo = <0x20>;
				qurgent_on = <0>;
				blocking_on = <0>;
			};
			npu_performance {
				stat_on = <1>;
				bypass = <0>;
				arqos = <0x4>;
				awqos = <0x4>;
				rmo = <0x8>;
				wmo = <0x8>;
				qurgent_on = <0>;
				blocking_on = <0>;
			};
		};
		/* NOCL1C D0_YUVP */
		bts_yuvp0 {
			reg = <0x0 0x1A6E8600 0x80>;
			status = "okay";
			bts-type = <IP_BTS>;
			cal-pdid = <0xB1380002>;
			default {
				stat_on = <1>;
				bypass = <0>;
				arqos = <0x4>;
				awqos = <0x4>;
				rmo = <0xC>;
				wmo = <0xC>;
				qurgent_on = <0>;
				blocking_on = <0>;
			};
		};
		/* NOCL1C D1_YUVP */
		bts_yuvp1 {
			reg = <0x0 0x1A6E8680 0x80>;
			status = "okay";
			bts-type = <IP_BTS>;
			cal-pdid = <0xB1380002>;
			default {
				stat_on = <1>;
				bypass = <0>;
				arqos = <0x4>;
				awqos = <0x4>;
				rmo = <0xC>;
				wmo = <0xC>;
				qurgent_on = <0>;
				blocking_on = <0>;
			};
		};
		/* NOCL1C ICPU */
		bts_icpu {
			reg = <0x0 0x1A6E8700 0x80>;
			status = "okay";
			bts-type = <IP_BTS>;
			cal-pdid = <0xB1380002>;
			default {
				stat_on = <1>;
				bypass = <0>;
				arqos = <0x4>;
				awqos = <0x4>;
				rmo = <0xFFFF>;
				wmo = <0xFFFF>;
				qurgent_on = <0>;
				blocking_on = <0>;
			};
		};
		/* G3D CRPControl for MO and SYSREG_NOCL for QoS */
		bts_g3d0 {
			reg = <0x0 0x1A000010 0x20>,	/* for MO */
			    <0x0 0x1A021280 0x10>;	/* for QoS */
			status = "okay";
			bts-type = <SCI_GPU_BTS>;
			default {
				stat_on = <1>;
				bypass = <0>;
				arqos = <0x0>;
				awqos = <0x0>;
				rmo = <0x10>;
				wmo = <0x10>;
			};
			g3d_heavy {
				stat_on = <1>;
				bypass = <0>;
				arqos = <0x0>;
				awqos = <0x0>;
				rmo = <0x40>;
				wmo = <0x40>;
			};
			g3d_performance {
				stat_on = <1>;
				bypass = <0>;
				arqos = <0x0>;
				awqos = <0x0>;
				rmo = <0x40>;
				wmo = <0x40>;
			};
			camera_default {
				stat_on = <1>;
				bypass = <0>;
				arqos = <0x0>;
				awqos = <0x0>;
				rmo = <0x8>;
				wmo = <0x8>;
			};
			npu_normal {
				stat_on = <1>;
				bypass = <0>;
				arqos = <0x0>;
				awqos = <0x0>;
				rmo = <0x8>;
				wmo = <0x8>;
			};
			mfc_uhd_enc60 {
				stat_on = <1>;
				bypass = <0>;
				arqos = <0x0>;
				awqos = <0x0>;
				rmo = <0x8>;
				wmo = <0x8>;
			};
			camera_heavy {
				stat_on = <1>;
				bypass = <0>;
				arqos = <0x0>;
				awqos = <0x0>;
				rmo = <0x8>;
				wmo = <0x8>;
			};
			npu_performance {
				stat_on = <1>;
				bypass = <0>;
				arqos = <0x0>;
				awqos = <0x0>;
				rmo = <0x40>;
				wmo = <0x40>;
			};
		};
		bts_g3d1 {
			reg = <0x0 0x1A000038 0x20>,	/* for MO */
			    <0x0 0x1A021290 0x10>;	/* for QoS */
			status = "okay";
			bts-type = <SCI_GPU_BTS>;
			default {
				stat_on = <1>;
				bypass = <0>;
				arqos = <0x0>;
				awqos = <0x0>;
				rmo = <0x10>;
				wmo = <0x10>;
			};
			g3d_heavy {
				stat_on = <1>;
				bypass = <0>;
				arqos = <0x0>;
				awqos = <0x0>;
				rmo = <0x40>;
				wmo = <0x40>;
			};
			g3d_performance {
				stat_on = <1>;
				bypass = <0>;
				arqos = <0x0>;
				awqos = <0x0>;
				rmo = <0x40>;
				wmo = <0x40>;
			};
			camera_default {
				stat_on = <1>;
				bypass = <0>;
				arqos = <0x0>;
				awqos = <0x0>;
				rmo = <0x8>;
				wmo = <0x8>;
			};
			npu_normal {
				stat_on = <1>;
				bypass = <0>;
				arqos = <0x0>;
				awqos = <0x0>;
				rmo = <0x8>;
				wmo = <0x8>;
			};
			mfc_uhd_enc60 {
				stat_on = <1>;
				bypass = <0>;
				arqos = <0x0>;
				awqos = <0x0>;
				rmo = <0x8>;
				wmo = <0x8>;
			};
			camera_heavy {
				stat_on = <1>;
				bypass = <0>;
				arqos = <0x0>;
				awqos = <0x0>;
				rmo = <0x8>;
				wmo = <0x8>;
			};
			npu_performance {
				stat_on = <1>;
				bypass = <0>;
				arqos = <0x0>;
				awqos = <0x0>;
				rmo = <0x40>;
				wmo = <0x40>;
			};
		};
		bts_g3d2 {
			reg = <0x0 0x1A000060 0x20>,	/* for MO */
			    <0x0 0x1A0212A0 0x10>;	/* for QoS */
			status = "okay";
			bts-type = <SCI_GPU_BTS>;
			default {
				stat_on = <1>;
				bypass = <0>;
				arqos = <0x0>;
				awqos = <0x0>;
				rmo = <0x10>;
				wmo = <0x10>;
			};
			g3d_heavy {
				stat_on = <1>;
				bypass = <0>;
				arqos = <0x0>;
				awqos = <0x0>;
				rmo = <0x40>;
				wmo = <0x40>;
			};
			g3d_performance {
				stat_on = <1>;
				bypass = <0>;
				arqos = <0x0>;
				awqos = <0x0>;
				rmo = <0x40>;
				wmo = <0x40>;
			};
			camera_default {
				stat_on = <1>;
				bypass = <0>;
				arqos = <0x0>;
				awqos = <0x0>;
				rmo = <0x8>;
				wmo = <0x8>;
			};
			npu_normal {
				stat_on = <1>;
				bypass = <0>;
				arqos = <0x0>;
				awqos = <0x0>;
				rmo = <0x8>;
				wmo = <0x8>;
			};
			mfc_uhd_enc60 {
				stat_on = <1>;
				bypass = <0>;
				arqos = <0x0>;
				awqos = <0x0>;
				rmo = <0x8>;
				wmo = <0x8>;
			};
			camera_heavy {
				stat_on = <1>;
				bypass = <0>;
				arqos = <0x0>;
				awqos = <0x0>;
				rmo = <0x8>;
				wmo = <0x8>;
			};
			npu_performance {
				stat_on = <1>;
				bypass = <0>;
				arqos = <0x0>;
				awqos = <0x0>;
				rmo = <0x40>;
				wmo = <0x40>;
			};
		};
		bts_g3d3 {
			reg = <0x0 0x1A000088 0x20>,	/* for MO */
			    <0x0 0x1A0212B0 0x10>;	/* for QoS */
			status = "okay";
			bts-type = <SCI_GPU_BTS>;
			default {
				stat_on = <1>;
				bypass = <0>;
				arqos = <0x0>;
				awqos = <0x0>;
				rmo = <0x10>;
				wmo = <0x10>;
			};
			g3d_heavy {
				stat_on = <1>;
				bypass = <0>;
				arqos = <0x0>;
				awqos = <0x0>;
				rmo = <0x40>;
				wmo = <0x40>;
			};
			g3d_performance {
				stat_on = <1>;
				bypass = <0>;
				arqos = <0x0>;
				awqos = <0x0>;
				rmo = <0x40>;
				wmo = <0x40>;
			};
			camera_default {
				stat_on = <1>;
				bypass = <0>;
				arqos = <0x0>;
				awqos = <0x0>;
				rmo = <0x8>;
				wmo = <0x8>;
			};
			npu_normal {
				stat_on = <1>;
				bypass = <0>;
				arqos = <0x0>;
				awqos = <0x0>;
				rmo = <0x8>;
				wmo = <0x8>;
			};
			mfc_uhd_enc60 {
				stat_on = <1>;
				bypass = <0>;
				arqos = <0x0>;
				awqos = <0x0>;
				rmo = <0x8>;
				wmo = <0x8>;
			};
			camera_heavy {
				stat_on = <1>;
				bypass = <0>;
				arqos = <0x0>;
				awqos = <0x0>;
				rmo = <0x8>;
				wmo = <0x8>;
			};
			npu_performance {
				stat_on = <1>;
				bypass = <0>;
				arqos = <0x0>;
				awqos = <0x0>;
				rmo = <0x40>;
				wmo = <0x40>;
			};
		};
		/* D_DNC */
		bts_dnc0 {
			reg = <0x0 0x166F8000 0x80>;
			status = "okay";
			bts-type = <IP_BTS>;
			cal-pdid = <0xB1380017>;
			default {
				stat_on = <1>;
				bypass = <0>;
				arqos = <0x4>;
				awqos = <0x4>;
				rmo = <0xC>;
				wmo = <0xC>;
				qurgent_on = <0>;
				blocking_on = <0>;
			};
			camera_default {
				stat_on = <1>;
				bypass = <0>;
				arqos = <0x4>;
				awqos = <0x4>;
				rmo = <0x30>;
				wmo = <0x30>;
				qurgent_on = <0>;
				blocking_on = <0>;
			};
			npu_normal {
				stat_on = <1>;
				bypass = <0>;
				arqos = <0x4>;
				awqos = <0x4>;
				rmo = <0x50>;
				wmo = <0x50>;
				qurgent_on = <0>;
				blocking_on = <0>;
			};
			camera_heavy {
				stat_on = <1>;
				bypass = <0>;
				arqos = <0x4>;
				awqos = <0x4>;
				rmo = <0x50>;
				wmo = <0x50>;
				qurgent_on = <0>;
				blocking_on = <0>;
			};
			npu_performance {
				stat_on = <1>;
				bypass = <0>;
				arqos = <0x4>;
				awqos = <0x4>;
				rmo = <0xFFFF>;
				wmo = <0xFFFF>;
				qurgent_on = <0>;
				blocking_on = <0>;
			};
		};
		/* D_DNC */
		bts_dnc1 {
			reg = <0x0 0x166F8080 0x80>;
			status = "okay";
			bts-type = <IP_BTS>;
			cal-pdid = <0xB1380017>;
			default {
				stat_on = <1>;
				bypass = <0>;
				arqos = <0x4>;
				awqos = <0x4>;
				rmo = <0xC>;
				wmo = <0xC>;
				qurgent_on = <0>;
				blocking_on = <0>;
			};
			camera_default {
				stat_on = <1>;
				bypass = <0>;
				arqos = <0x4>;
				awqos = <0x4>;
				rmo = <0x30>;
				wmo = <0x30>;
				qurgent_on = <0>;
				blocking_on = <0>;
			};
			npu_normal {
				stat_on = <1>;
				bypass = <0>;
				arqos = <0x4>;
				awqos = <0x4>;
				rmo = <0x50>;
				wmo = <0x50>;
				qurgent_on = <0>;
				blocking_on = <0>;
			};
			camera_heavy {
				stat_on = <1>;
				bypass = <0>;
				arqos = <0x4>;
				awqos = <0x4>;
				rmo = <0x50>;
				wmo = <0x50>;
				qurgent_on = <0>;
				blocking_on = <0>;
			};
			npu_performance {
				stat_on = <1>;
				bypass = <0>;
				arqos = <0x4>;
				awqos = <0x4>;
				rmo = <0xFFFF>;
				wmo = <0xFFFF>;
				qurgent_on = <0>;
				blocking_on = <0>;
			};
		};
		/* D_DNC */
		bts_dnc2 {
			reg = <0x0 0x166F8100 0x80>;
			status = "okay";
			bts-type = <IP_BTS>;
			cal-pdid = <0xB1380017>;
			default {
				stat_on = <1>;
				bypass = <0>;
				arqos = <0x4>;
				awqos = <0x4>;
				rmo = <0xC>;
				wmo = <0xC>;
				qurgent_on = <0>;
				blocking_on = <0>;
			};
			camera_default {
				stat_on = <1>;
				bypass = <0>;
				arqos = <0x4>;
				awqos = <0x4>;
				rmo = <0x30>;
				wmo = <0x30>;
				qurgent_on = <0>;
				blocking_on = <0>;
			};
			npu_normal {
				stat_on = <1>;
				bypass = <0>;
				arqos = <0x4>;
				awqos = <0x4>;
				rmo = <0x50>;
				wmo = <0x50>;
				qurgent_on = <0>;
				blocking_on = <0>;
			};
			camera_heavy {
				stat_on = <1>;
				bypass = <0>;
				arqos = <0x4>;
				awqos = <0x4>;
				rmo = <0x50>;
				wmo = <0x50>;
				qurgent_on = <0>;
				blocking_on = <0>;
			};
			npu_performance {
				stat_on = <1>;
				bypass = <0>;
				arqos = <0x4>;
				awqos = <0x4>;
				rmo = <0xFFFF>;
				wmo = <0xFFFF>;
				qurgent_on = <0>;
				blocking_on = <0>;
			};
		};
		/* D_DNC */
		bts_dnc3 {
			reg = <0x0 0x166F8180 0x80>;
			status = "okay";
			bts-type = <IP_BTS>;
			cal-pdid = <0xB1380017>;
			default {
				stat_on = <1>;
				bypass = <0>;
				arqos = <0x4>;
				awqos = <0x4>;
				rmo = <0xC>;
				wmo = <0xC>;
				qurgent_on = <0>;
				blocking_on = <0>;
			};
			camera_default {
				stat_on = <1>;
				bypass = <0>;
				arqos = <0x4>;
				awqos = <0x4>;
				rmo = <0x30>;
				wmo = <0x30>;
				qurgent_on = <0>;
				blocking_on = <0>;
			};
			npu_normal {
				stat_on = <1>;
				bypass = <0>;
				arqos = <0x4>;
				awqos = <0x4>;
				rmo = <0x50>;
				wmo = <0x50>;
				qurgent_on = <0>;
				blocking_on = <0>;
			};
			camera_heavy {
				stat_on = <1>;
				bypass = <0>;
				arqos = <0x4>;
				awqos = <0x4>;
				rmo = <0x50>;
				wmo = <0x50>;
				qurgent_on = <0>;
				blocking_on = <0>;
			};
			npu_performance {
				stat_on = <1>;
				bypass = <0>;
				arqos = <0x4>;
				awqos = <0x4>;
				rmo = <0xFFFF>;
				wmo = <0xFFFF>;
				qurgent_on = <0>;
				blocking_on = <0>;
			};
		};
		/* D_DNC */
		bts_dnc4 {
			reg = <0x0 0x166F8200 0x80>;
			status = "okay";
			bts-type = <IP_BTS>;
			cal-pdid = <0xB1380017>;
			default {
				stat_on = <1>;
				bypass = <0>;
				arqos = <0x4>;
				awqos = <0x4>;
				rmo = <0xC>;
				wmo = <0xC>;
				qurgent_on = <0>;
				blocking_on = <0>;
			};
			camera_default {
				stat_on = <1>;
				bypass = <0>;
				arqos = <0x4>;
				awqos = <0x4>;
				rmo = <0x30>;
				wmo = <0x30>;
				qurgent_on = <0>;
				blocking_on = <0>;
			};
			npu_normal {
				stat_on = <1>;
				bypass = <0>;
				arqos = <0x4>;
				awqos = <0x4>;
				rmo = <0x50>;
				wmo = <0x50>;
				qurgent_on = <0>;
				blocking_on = <0>;
			};
			camera_heavy {
				stat_on = <1>;
				bypass = <0>;
				arqos = <0x4>;
				awqos = <0x4>;
				rmo = <0x50>;
				wmo = <0x50>;
				qurgent_on = <0>;
				blocking_on = <0>;
			};
			npu_performance {
				stat_on = <1>;
				bypass = <0>;
				arqos = <0x4>;
				awqos = <0x4>;
				rmo = <0xFFFF>;
				wmo = <0xFFFF>;
				qurgent_on = <0>;
				blocking_on = <0>;
			};
		};
	};
};
